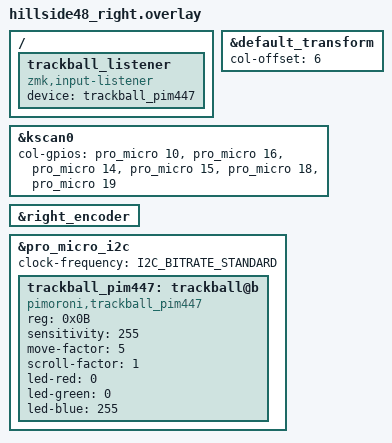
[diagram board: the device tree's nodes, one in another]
/*
 * Copyright (c) 2021 The ZMK Contributors
 *
 * SPDX-License-Identifier: MIT
 */

#include "hillside48.dtsi"

&default_transform {
    col-offset = <6>;
};

&kscan0 {
    col-gpios
        = <&pro_micro 10 GPIO_ACTIVE_HIGH> // col5 in the schematic
        , <&pro_micro 16 GPIO_ACTIVE_HIGH> // col4 in the schematic
        , <&pro_micro 14 GPIO_ACTIVE_HIGH> // col3 in the schematic
        , <&pro_micro 15 GPIO_ACTIVE_HIGH> // col2 in the schematic
        , <&pro_micro 18 GPIO_ACTIVE_HIGH> // col1 in the schematic
        , <&pro_micro 19 GPIO_ACTIVE_HIGH> // col0 in the schematic
        ;
};

&right_encoder {
    status = "okay";
};

&pro_micro_i2c {
    status = "okay";
    clock-frequency = <I2C_BITRATE_STANDARD>;

    trackball_pim447: trackball@b {
        compatible = "pimoroni,trackball_pim447";
        reg = <0x0B>;
        sensitivity = <255>;
        move-factor = <5>;
        scroll-factor = <1>;
        led-red = <0>;
        led-green = <0>;
        led-blue = <255>;
    };
};

/ {
    trackball_listener: trackball_listener {
        compatible = "zmk,input-listener";
        device = <&trackball_pim447>;
    };
};
